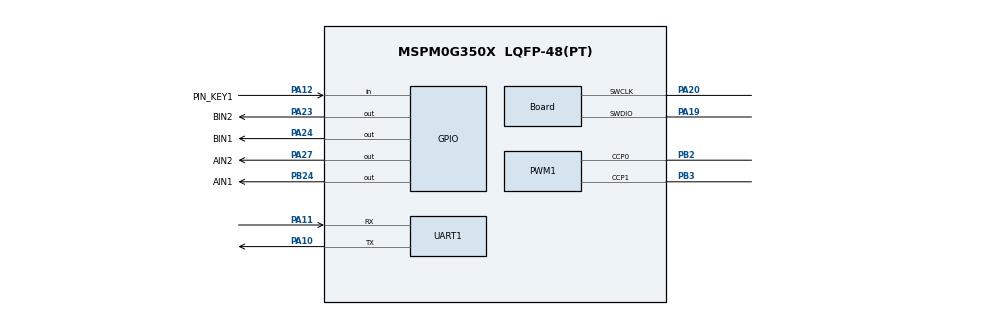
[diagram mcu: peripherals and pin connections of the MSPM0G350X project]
/**
 * @cliArgs --device "MSPM0G350X" --part "Default" --package "LQFP-48(PT)" --product "mspm0_sdk@2.01.00.03"
 * @versions {"tool":"1.24.1+4189"}
 */

/**
 * Import the modules used in this configuration.
 */
const GPIO          = scripting.addModule("/ti/driverlib/GPIO", {}, false);
const GPIO1         = GPIO.addInstance();
const GPIO2         = GPIO.addInstance();
const GPIO3         = GPIO.addInstance();
const GPIO4         = GPIO.addInstance();
const GPIO5         = GPIO.addInstance();
const GPIO6         = GPIO.addInstance();
const PWM           = scripting.addModule("/ti/driverlib/PWM", {}, false);
const PWM1          = PWM.addInstance();
const SYSCTL        = scripting.addModule("/ti/driverlib/SYSCTL");
const SYSTICK       = scripting.addModule("/ti/driverlib/SYSTICK");
const TIMER         = scripting.addModule("/ti/driverlib/TIMER", {}, false);
const TIMER1        = TIMER.addInstance();
const UART          = scripting.addModule("/ti/driverlib/UART", {}, false);
const UART1         = UART.addInstance();
const ProjectConfig = scripting.addModule("/ti/project_config/ProjectConfig");

/**
 * Write custom configuration values to the imported modules.
 */
const divider7       = system.clockTree["PLL_PDIV"];
divider7.divideValue = 2;

const divider9       = system.clockTree["UDIV"];
divider9.divideValue = 2;

const gate7  = system.clockTree["MFCLKGATE"];
gate7.enable = true;

const multiplier2         = system.clockTree["PLL_QDIV"];
multiplier2.multiplyValue = 10;

const mux8       = system.clockTree["HSCLKMUX"];
mux8.inputSelect = "HSCLKMUX_SYSPLL0";

const pinFunction3     = system.clockTree["HFCLKEXT"];
pinFunction3.inputFreq = 80;

GPIO1.$name                          = "MOTOR";
GPIO1.associatedPins.create(4);
GPIO1.associatedPins[0].assignedPort = "PORTB";
GPIO1.associatedPins[0].assignedPin  = "24";
GPIO1.associatedPins[0].$name        = "AIN1";
GPIO1.associatedPins[0].pin.$assign  = "PB24";
GPIO1.associatedPins[1].$name        = "AIN2";
GPIO1.associatedPins[1].assignedPort = "PORTA";
GPIO1.associatedPins[1].assignedPin  = "27";
GPIO1.associatedPins[1].pin.$assign  = "PA27";
GPIO1.associatedPins[2].$name        = "BIN1";
GPIO1.associatedPins[2].assignedPort = "PORTA";
GPIO1.associatedPins[2].assignedPin  = "24";
GPIO1.associatedPins[2].pin.$assign  = "PA24";
GPIO1.associatedPins[3].$name        = "BIN2";
GPIO1.associatedPins[3].assignedPort = "PORTA";
GPIO1.associatedPins[3].assignedPin  = "23";
GPIO1.associatedPins[3].pin.$assign  = "PA23";

const Board                       = scripting.addModule("/ti/driverlib/Board", {}, false);
Board.peripheral.$assign          = "DEBUGSS";
Board.peripheral.swclkPin.$assign = "PA20";
Board.peripheral.swdioPin.$assign = "PA19";

GPIO2.$name                              = "GPIO_GRP_0";
GPIO2.associatedPins[0].$name            = "PIN_KEY1";
GPIO2.associatedPins[0].direction        = "INPUT";
GPIO2.associatedPins[0].assignedPin      = "12";
GPIO2.associatedPins[0].internalResistor = "PULL_UP";
GPIO2.associatedPins[0].assignedPort     = "PORTA";
GPIO2.associatedPins[0].pin.$assign      = "PA12";

GPIO3.$name                          = "GPIO_GRP_Detect";
GPIO3.associatedPins.create(6);
GPIO3.associatedPins[0].$name        = "PIN_X1";
GPIO3.associatedPins[0].direction    = "INPUT";
GPIO3.associatedPins[0].assignedPort = "PORTB";
GPIO3.associatedPins[0].assignedPin  = "6";
GPIO3.associatedPins[1].$name        = "PIN_X2";
GPIO3.associatedPins[1].direction    = "INPUT";
GPIO3.associatedPins[1].assignedPort = "PORTA";
GPIO3.associatedPins[1].assignedPin  = "9";
GPIO3.associatedPins[2].$name        = "PIN_X3";
GPIO3.associatedPins[2].direction    = "INPUT";
GPIO3.associatedPins[2].assignedPort = "PORTA";
GPIO3.associatedPins[2].assignedPin  = "8";
GPIO3.associatedPins[3].$name        = "PIN_X4";
GPIO3.associatedPins[3].direction    = "INPUT";
GPIO3.associatedPins[3].assignedPort = "PORTA";
GPIO3.associatedPins[3].assignedPin  = "7";
GPIO3.associatedPins[4].$name        = "PIN_X5";
GPIO3.associatedPins[4].direction    = "INPUT";
GPIO3.associatedPins[4].assignedPort = "PORTA";
GPIO3.associatedPins[4].assignedPin  = "16";
GPIO3.associatedPins[5].$name        = "PIN_X6";
GPIO3.associatedPins[5].direction    = "INPUT";
GPIO3.associatedPins[5].assignedPort = "PORTA";
GPIO3.associatedPins[5].assignedPin  = "17";

GPIO4.$name                               = "ENCODER";
GPIO4.associatedPins.create(4);
GPIO4.associatedPins[0].$name             = "E1A";
GPIO4.associatedPins[0].direction         = "INPUT";
GPIO4.associatedPins[0].assignedPort      = "PORTA";
GPIO4.associatedPins[0].assignedPin       = "25";
GPIO4.associatedPins[0].interruptEn       = true;
GPIO4.associatedPins[0].polarity          = "RISE";
GPIO4.associatedPins[0].interruptPriority = "1";
GPIO4.associatedPins[1].$name             = "E1B";
GPIO4.associatedPins[1].direction         = "INPUT";
GPIO4.associatedPins[1].assignedPort      = "PORTA";
GPIO4.associatedPins[1].assignedPin       = "26";
GPIO4.associatedPins[1].interruptEn       = true;
GPIO4.associatedPins[1].polarity          = "RISE";
GPIO4.associatedPins[1].interruptPriority = "1";
GPIO4.associatedPins[2].$name             = "E2A";
GPIO4.associatedPins[2].direction         = "INPUT";
GPIO4.associatedPins[2].assignedPort      = "PORTB";
GPIO4.associatedPins[2].assignedPin       = "19";
GPIO4.associatedPins[2].interruptEn       = true;
GPIO4.associatedPins[2].polarity          = "RISE";
GPIO4.associatedPins[2].interruptPriority = "1";
GPIO4.associatedPins[3].$name             = "E2B";
GPIO4.associatedPins[3].direction         = "INPUT";
GPIO4.associatedPins[3].assignedPort      = "PORTB";
GPIO4.associatedPins[3].assignedPin       = "20";
GPIO4.associatedPins[3].interruptEn       = true;
GPIO4.associatedPins[3].polarity          = "RISE";
GPIO4.associatedPins[3].interruptPriority = "1";

GPIO5.$name                          = "GPIO_sda";
GPIO5.associatedPins[0].$name        = "PIN_0";
GPIO5.associatedPins[0].assignedPort = "PORTA";
GPIO5.associatedPins[0].assignedPin  = "0";
GPIO5.associatedPins[0].ioStructure  = "OD";

GPIO6.$name                         = "GPIO_scl";
GPIO6.port                          = "PORTA";
GPIO6.associatedPins[0].$name       = "PIN_1";
GPIO6.associatedPins[0].assignedPin = "1";
GPIO6.associatedPins[0].ioStructure = "OD";

PWM1.timerCount                         = 2000;
PWM1.$name                              = "PWM_AB";
PWM1.clockPrescale                      = 32;
PWM1.peripheral.$assign                 = "TIMA1";
PWM1.peripheral.ccp0Pin.$assign         = "PB2";
PWM1.peripheral.ccp1Pin.$assign         = "PB3";
PWM1.PWM_CHANNEL_0.$name                = "ti_driverlib_pwm_PWMTimerCC0";
PWM1.PWM_CHANNEL_0.dutyCycle            = 75;
PWM1.PWM_CHANNEL_1.$name                = "ti_driverlib_pwm_PWMTimerCC1";
PWM1.PWM_CHANNEL_1.dutyCycle            = 75;
PWM1.PWM_CHANNEL_1.ccValue              = 500;
PWM1.ccp0PinConfig.direction            = scripting.forceWrite("OUTPUT");
PWM1.ccp0PinConfig.hideOutputInversion  = scripting.forceWrite(false);
PWM1.ccp0PinConfig.onlyInternalResistor = scripting.forceWrite(false);
PWM1.ccp0PinConfig.passedPeripheralType = scripting.forceWrite("Digital");
PWM1.ccp0PinConfig.$name                = "ti_driverlib_gpio_GPIOPinGeneric2";
PWM1.ccp1PinConfig.direction            = scripting.forceWrite("OUTPUT");
PWM1.ccp1PinConfig.hideOutputInversion  = scripting.forceWrite(false);
PWM1.ccp1PinConfig.onlyInternalResistor = scripting.forceWrite(false);
PWM1.ccp1PinConfig.passedPeripheralType = scripting.forceWrite("Digital");
PWM1.ccp1PinConfig.$name                = "ti_driverlib_gpio_GPIOPinGeneric3";

SYSCTL.clockTreeEn           = true;
SYSCTL.forceDefaultClkConfig = true;

SYSTICK.periodEnable      = true;
SYSTICK.systickEnable     = true;
SYSTICK.interruptPriority = "0";
SYSTICK.period            = 80;

TIMER1.$name            = "TIMER_0";
TIMER1.timerClkPrescale = 80;
TIMER1.timerPeriod      = "10 ms";
TIMER1.timerStartTimer  = true;
TIMER1.interrupts       = ["ZERO"];
TIMER1.timerMode        = "PERIODIC_UP";

UART1.$name                    = "UART_0";
UART1.uartClkSrc               = "MFCLK";
UART1.enabledInterrupts        = ["RX"];
UART1.targetBaudRate           = 115200;
UART1.peripheral.$assign       = "UART0";
UART1.peripheral.rxPin.$assign = "PA11";
UART1.peripheral.txPin.$assign = "PA10";
UART1.txPinConfig.$name        = "ti_driverlib_gpio_GPIOPinGeneric0";
UART1.rxPinConfig.$name        = "ti_driverlib_gpio_GPIOPinGeneric1";

ProjectConfig.deviceSpin = "MSPM0G3507";

/**
 * Pinmux solution for unlocked pins/peripherals. This ensures that minor changes to the automatic solver in a future
 * version of the tool will not impact the pinmux you originally saw.  These lines can be completely deleted in order to
 * re-solve from scratch.
 */
GPIO3.associatedPins[0].pin.$suggestSolution = "PB6";
GPIO3.associatedPins[1].pin.$suggestSolution = "PA9";
GPIO3.associatedPins[2].pin.$suggestSolution = "PA8";
GPIO3.associatedPins[3].pin.$suggestSolution = "PA7";
GPIO3.associatedPins[4].pin.$suggestSolution = "PA16";
GPIO3.associatedPins[5].pin.$suggestSolution = "PA17";
GPIO4.associatedPins[0].pin.$suggestSolution = "PA25";
GPIO4.associatedPins[1].pin.$suggestSolution = "PA26";
GPIO4.associatedPins[2].pin.$suggestSolution = "PB19";
GPIO4.associatedPins[3].pin.$suggestSolution = "PB20";
GPIO5.associatedPins[0].pin.$suggestSolution = "PA0";
GPIO6.associatedPins[0].pin.$suggestSolution = "PA1";
TIMER1.peripheral.$suggestSolution           = "TIMA0";
